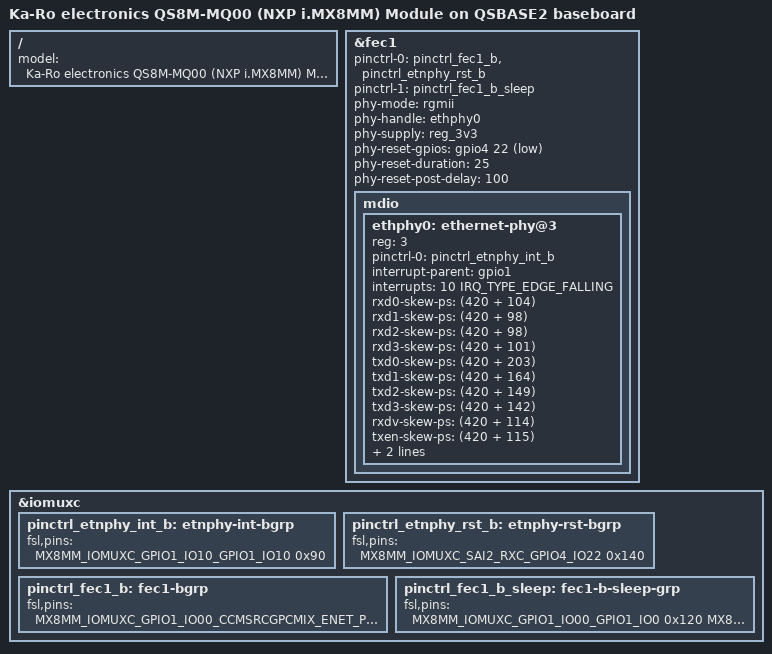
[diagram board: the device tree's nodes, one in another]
// SPDX-License-Identifier: (GPL-2.0 OR MIT)
/*
 * Copyright (C) 2019 Lothar Waßmann <LW@KARO-electronics.de>
 *
 */

/dts-v1/;

#include "imx8mm-qs8m-mq00.dts"

/ {
	model = "Ka-Ro electronics QS8M-MQ00 (NXP i.MX8MM) Module on QSBASE2 baseboard";
};

&fec1 {
	pinctrl-names = "default", "sleep";
	pinctrl-0 = <&pinctrl_fec1_b &pinctrl_etnphy_rst_b>;
	pinctrl-1 = <&pinctrl_fec1_b_sleep>;
	phy-mode = "rgmii";
	phy-handle = <&ethphy0>;
	phy-supply = <&reg_3v3>;
	phy-reset-gpios = <&gpio4 22 GPIO_ACTIVE_LOW>;
	phy-reset-duration = <25>;
	phy-reset-post-delay = <100>;
	status = "okay";

	mdio {
		#address-cells = <1>;
		#size-cells = <0>;

		ethphy0: ethernet-phy@3 {
			reg = <3>;
			pinctrl-names = "default";
			pinctrl-0 = <&pinctrl_etnphy_int_b>;
			interrupt-parent = <&gpio1>;
			interrupts = <10 IRQ_TYPE_EDGE_FALLING>;
			rxd0-skew-ps = <(420 + 104)>;
			rxd1-skew-ps = <(420 + 98)>;
			rxd2-skew-ps = <(420 + 98)>;
			rxd3-skew-ps = <(420 + 101)>;
			txd0-skew-ps = <(420 + 203)>;
			txd1-skew-ps = <(420 + 164)>;
			txd2-skew-ps = <(420 + 149)>;
			txd3-skew-ps = <(420 + 142)>;
			rxdv-skew-ps = <(420 + 114)>;
			txen-skew-ps = <(420 + 115)>;
			rxc-skew-ps = <(900 + 140)>;
			txc-skew-ps = <(900 + 132)>;
		};
	};
};

&iomuxc {
	pinctrl_etnphy_int_b: etnphy-int-bgrp {
		fsl,pins = <
			    MX8MM_IOMUXC_GPIO1_IO10_GPIO1_IO10		0x90
		>;
	};

	pinctrl_etnphy_rst_b: etnphy-rst-bgrp {
		fsl,pins = <
			    MX8MM_IOMUXC_SAI2_RXC_GPIO4_IO22		0x140
		>;
	};

	pinctrl_fec1_b: fec1-bgrp {
		fsl,pins = <
			    MX8MM_IOMUXC_GPIO1_IO00_CCMSRCGPCMIX_ENET_PHY_REF_CLK_ROOT 0x110
			    MX8MM_IOMUXC_ENET_MDC_ENET1_MDC		0x142
			    MX8MM_IOMUXC_ENET_MDIO_ENET1_MDIO		0x142
			    MX8MM_IOMUXC_ENET_TXC_ENET1_RGMII_TXC	0x40000016
			    MX8MM_IOMUXC_ENET_TD0_ENET1_RGMII_TD0	0x016
			    MX8MM_IOMUXC_ENET_TD1_ENET1_RGMII_TD1	0x016
			    MX8MM_IOMUXC_ENET_TD2_ENET1_RGMII_TD2	0x016
			    MX8MM_IOMUXC_ENET_TD3_ENET1_RGMII_TD3	0x016
			    MX8MM_IOMUXC_ENET_RD0_ENET1_RGMII_RD0	0x150
			    MX8MM_IOMUXC_ENET_RD1_ENET1_RGMII_RD1	0x150
			    MX8MM_IOMUXC_ENET_RD2_ENET1_RGMII_RD2	0x150
			    MX8MM_IOMUXC_ENET_RD3_ENET1_RGMII_RD3	0x150
			    MX8MM_IOMUXC_ENET_RXC_ENET1_RGMII_RXC	0x116
			    MX8MM_IOMUXC_ENET_RX_CTL_ENET1_RGMII_RX_CTL	0x116
			    MX8MM_IOMUXC_ENET_TX_CTL_ENET1_RGMII_TX_CTL	0x016
		>;
	};

	pinctrl_fec1_b_sleep: fec1-b-sleep-grp {
		fsl,pins = <
			    MX8MM_IOMUXC_GPIO1_IO00_GPIO1_IO0		0x120
			    MX8MM_IOMUXC_ENET_MDC_GPIO1_IO16		0x120
			    MX8MM_IOMUXC_ENET_MDIO_GPIO1_IO17		0x120
			    MX8MM_IOMUXC_ENET_TXC_GPIO1_IO23		0x40000120
			    MX8MM_IOMUXC_ENET_TD0_GPIO1_IO21		0x120
			    MX8MM_IOMUXC_ENET_TD1_GPIO1_IO20		0x120
			    MX8MM_IOMUXC_ENET_TD2_GPIO1_IO19		0x120
			    MX8MM_IOMUXC_ENET_TD3_GPIO1_IO18		0x120
			    MX8MM_IOMUXC_ENET_RD0_GPIO1_IO26		0x120
			    MX8MM_IOMUXC_ENET_RD1_GPIO1_IO27		0x120
			    MX8MM_IOMUXC_ENET_RD2_GPIO1_IO28		0x120
			    MX8MM_IOMUXC_ENET_RD3_GPIO1_IO29		0x120
			    MX8MM_IOMUXC_ENET_RXC_GPIO1_IO25		0x120
			    MX8MM_IOMUXC_ENET_RX_CTL_GPIO1_IO24		0x120
			    MX8MM_IOMUXC_ENET_TX_CTL_GPIO1_IO22		0x120
		>;
	};
};
